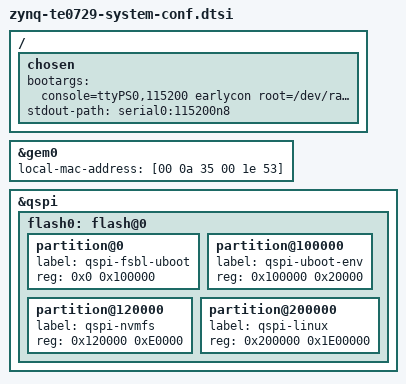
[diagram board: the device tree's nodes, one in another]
/*
 * CAUTION: This file is automatically generated by PetaLinux SDK.
 * DO NOT modify this file
 */


/ {
        chosen {
                bootargs = "console=ttyPS0,115200 earlycon root=/dev/ram0 rw";
                stdout-path = "serial0:115200n8";
        };
};

&gem0 {
        local-mac-address = [00 0a 35 00 1e 53];
};

&qspi {
        flash0: flash@0 {
                partition@0 {
                        label = "qspi-fsbl-uboot";
                        reg = <0x0 0x100000>; /* 1M */
                };
                partition@100000 {
                        label = "qspi-uboot-env";
                        reg = <0x100000 0x20000>; /* 128k */
                };
                partition@120000 {
                        label = "qspi-nvmfs";
                        reg = <0x120000 0xE0000>; /* 1M */
                };
                partition@200000 {
                        label = "qspi-linux";
                        reg = <0x200000 0x1E00000>; /* 30M */
                };

/*
                partition@0 {
                        label = "qspi-boot";
                        reg = <0x00000000 0x00100000>;
                };
                partition@1 {
                        label = "qspi-kernel";
                        reg = <0x00100000 0x01400000>;
                };
                partition@2 {
                        label = "qspi-bootenv";
                        reg = <0x01500000 0x00020000>;
                };
                partition@3 {
                        label = "bootscr";
                        reg = <0x01520000 0x00040000>;
                };
*/
        };
};
